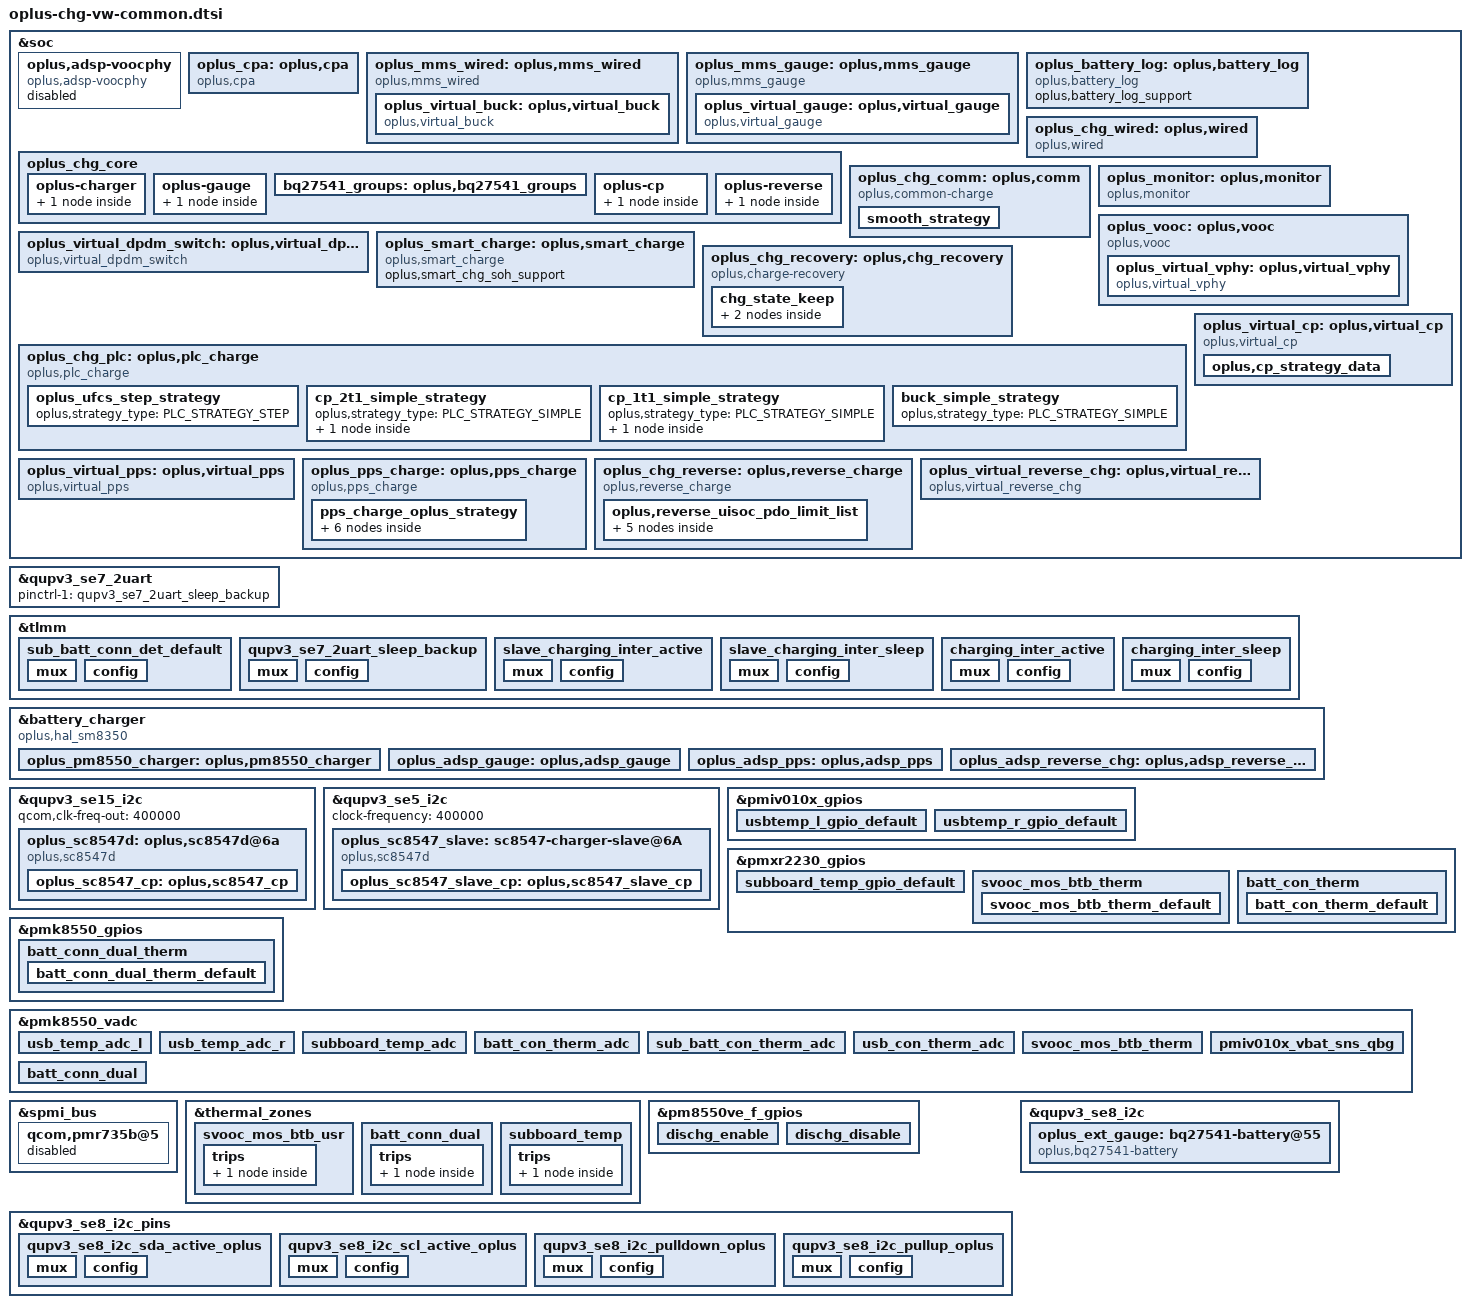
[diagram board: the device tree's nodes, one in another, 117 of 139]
//ifdef OPLUS_FEATURE_CHG_BASIC
#include "../oplus-chg-8750.h.dtsi"
#include <dt-bindings/iio/qcom,spmi-adc5-gen3-pmk8550.h>
#include <dt-bindings/iio/qcom,spmi-adc5-gen3-pm8550.h>
#include <dt-bindings/iio/qcom,spmi-adc5-gen3-pm8550b.h>
#include <dt-bindings/iio/qcom,spmi-adc5-gen3-pm8550vx.h>
#include <dt-bindings/iio/qcom,spmi-adc5-gen3-pmiv0104.h>

&soc {
	oplus,adsp-voocphy {
		status = "disabled";
		compatible = "oplus,adsp-voocphy";
	};
	oplus_cpa: oplus,cpa {
		compatible = "oplus,cpa";
		oplus,protocol_list = <CHG_PROTOCOL_PD   18
					CHG_PROTOCOL_VOOC 80
					CHG_PROTOCOL_QC   18>;
		oplus,default_protocol_list = <CHG_PROTOCOL_PD
						CHG_PROTOCOL_VOOC>;
	};

	oplus_mms_wired: oplus,mms_wired {
		compatible = "oplus,mms_wired";
		oplus,buck_ic = <&oplus_virtual_buck>;
		oplus,voocphy_ic = <&oplus_virtual_vphy>;
		oplus,adc_info_name = "855";
		oplus,topic-update-interval = <5000>;
		high-temp-scheme;
		oplus,support_usbtemp_protect_v2;
		oplus_spec,usbtemp_batt_temp_low = <50>;
		oplus_spec,usbtemp_batt_temp_high = <50>;
		oplus_spec,usbtemp_batt_temp_over_hot = <60>;
		oplus_spec,usbtemp_ntc_temp_low = <57>;
		oplus_spec,usbtemp_ntc_temp_high = <69>;
		oplus_spec,usbtemp_temp_gap_low_with_batt_temp = <7>;
		oplus_spec,usbtemp_temp_gap_with_batt_temp_in_over_hot = <15>;
		oplus_spec,usbtemp_temp_gap_high_with_batt_temp = <12>;
		oplus_spec,usbtemp_temp_gap_low_without_batt_temp = <12>;
		oplus_spec,usbtemp_temp_gap_high_without_batt_temp = <24>;
		oplus_spec,usbtemp_rise_fast_temp_low = <3>;
		oplus_spec,usbtemp_rise_fast_temp_high = <3>;
		oplus_spec,usbtemp_rise_fast_temp_count_low = <30>;
		oplus_spec,usbtemp_rise_fast_temp_count_high = <20>;
		oplus_spec,usbtemp_cool_down_ntc_low = <54>;
		oplus_spec,usbtemp_cool_down_ntc_high = <65>;
		oplus_spec,usbtemp_cool_down_gap_low = <12>;
		oplus_spec,usbtemp_cool_down_gap_high = <20>;
		oplus_spec,usbtemp_cool_down_recover_ntc_low = <48>;
		oplus_spec,usbtemp_cool_down_recover_ntc_high = <60>;
		oplus_spec,usbtemp_cool_down_recover_gap_low = <6>;
		oplus_spec,usbtemp_cool_down_recover_gap_high = <15>;
		oplus_spec,usbtemp_otg_cc_boot_current_limit = <1500>;

		oplus_virtual_buck: oplus,virtual_buck {
			compatible = "oplus,virtual_buck";
			oplus,buck_ic = <&oplus_pm8550_charger>;
			oplus,buck_ic_index = <0>;
			oplus,buck_ic_connect = <OPLUS_CHG_IC_CONNECT_PARALLEL>;
			oplus,main_charger = <1>;
			oplus,buck_ic_current_ratio = <100>;
			oplus,buck_ic_func_group = <&plat_pm8550_groups>;

			oplus,ic_type = <OPLUS_CHG_IC_VIRTUAL_BUCK>;
			oplus,ic_index = <0>;

			oplus,dischg-gpio = <&pm8550ve_f_gpios 7 0x00>;

			pinctrl-names = "usbtemp_l_gpio_default", "usbtemp_r_gpio_default",
					"dischg_enable", "dischg_disable";
			pinctrl-0 = <&usbtemp_l_gpio_default>;
			pinctrl-1 = <&usbtemp_r_gpio_default>;
			pinctrl-2 = <&dischg_enable>;
			pinctrl-3 = <&dischg_disable>;


			io-channels = <&pmk8550_vadc PMIV0104_ADC5_GEN3_AMUX_THM6_GPIO6_100K_PU>,
					      <&pmk8550_vadc PMIV0104_ADC5_GEN3_AMUX3_GPIO7_100K_PU>;
			io-channel-names = "usb_temp_adc_l", "usb_temp_adc_r";

			oplus,uart_tx-gpio = <&tlmm 30 0x00>;
			oplus,uart_rx-gpio = <&tlmm 31 0x00>;
		};
	};

	oplus_mms_gauge: oplus,mms_gauge {
		compatible = "oplus,mms_gauge";
		oplus,gauge_ic = <&oplus_virtual_gauge>;
		oplus,topic-update-interval = <5000>;
		oplus,support_subboard_ntc;
		oplus,sub_btb_curr_limit = <3000>;
		oplus,fcl_support;
		oplus,fcl_index = <0>;
		oplus,vb_offset = <20>;

		oplus_virtual_gauge: oplus,virtual_gauge {
			compatible = "oplus,virtual_gauge";
			oplus,gauge_ic = <&oplus_adsp_gauge &oplus_ext_gauge>;
			oplus,gauge_ic_index = <0 1>;
			oplus,gauge_ic_func_group = <&adsp_gauge_groups &bq27541_groups>;
			oplus,ic_type = <OPLUS_CHG_IC_VIRTUAL_GAUGE>;
			oplus,ic_index = <0>;

			oplus,batt_sub_btb-gpio = <&tlmm 134 0x00>;
			pinctrl-names = "default";
			pinctrl-0 = <&sub_batt_conn_det_default>;
		};
	};

	oplus_chg_core: oplus_chg_core {
		oplus,chg_framework_v2;
		oplus,battery_type_by_smem;
		oplus,smart_charging_screenoff;
		oplus,chg_spec_version = <OPLUS_CHG_SPEC_VER_V3P7>;
		oplus,common-charge-icl-support;

		oplus-charger {
			plat_pm8550_groups: oplus,plat_pm8550-groups {
				functions = <
					OPLUS_IC_FUNC_INIT
					OPLUS_IC_FUNC_EXIT
					OPLUS_IC_FUNC_REG_DUMP
					OPLUS_IC_FUNC_SMT_TEST
					OPLUS_IC_FUNC_BUCK_INPUT_PRESENT
					OPLUS_IC_FUNC_BUCK_INPUT_SUSPEND
					OPLUS_IC_FUNC_BUCK_INPUT_IS_SUSPEND
					OPLUS_IC_FUNC_BUCK_OUTPUT_SUSPEND
					OPLUS_IC_FUNC_BUCK_OUTPUT_IS_SUSPEND
					OPLUS_IC_FUNC_BUCK_GET_CC_ORIENTATION
					OPLUS_IC_FUNC_BUCK_GET_CHARGER_TYPE
					OPLUS_IC_FUNC_BUCK_RERUN_BC12
					OPLUS_IC_FUNC_BUCK_QC_DETECT_ENABLE
					OPLUS_IC_FUNC_BUCK_SHIPMODE_ENABLE
					OPLUS_IC_FUNC_BUCK_SET_QC_CONFIG
					OPLUS_IC_FUNC_BUCK_SET_PD_CONFIG
					OPLUS_IC_FUNC_GET_SHUTDOWN_SOC
					OPLUS_IC_FUNC_BACKUP_SOC
					OPLUS_IC_FUNC_GET_TYPEC_MODE
					OPLUS_IC_FUNC_BUCK_SET_ICL
					OPLUS_IC_FUNC_BUCK_GET_ICL
					OPLUS_IC_FUNC_BUCK_SET_FCC
					OPLUS_IC_FUNC_BUCK_SET_FV
					OPLUS_IC_FUNC_BUCK_SET_ITERM
					OPLUS_IC_FUNC_BUCK_SET_RECHG_VOL
					OPLUS_IC_FUNC_BUCK_GET_INPUT_CURR
					OPLUS_IC_FUNC_BUCK_GET_INPUT_VOL
					OPLUS_IC_FUNC_BUCK_ITEM_CHECK
					OPLUS_IC_FUNC_GET_CHARGER_CYCLE
					OPLUS_IC_FUNC_OTG_BOOST_ENABLE
					OPLUS_IC_FUNC_SET_OTG_BOOST_CURR_LIMIT
					OPLUS_IC_FUNC_BUCK_GET_VBUS_COLLAPSE_STATUS
					OPLUS_IC_FUNC_GET_OTG_ENABLE
					OPLUS_IC_FUNC_SET_OTG_SWITCH_STATUS
					OPLUS_IC_FUNC_GET_OTG_SWITCH_STATUS
					OPLUS_IC_FUNC_GET_OTG_ONLINE_STATUS
					OPLUS_IC_FUNC_BUCK_GET_HW_DETECT
					OPLUS_IC_FUNC_VOOCPHY_SET_MATCH_TEMP
					OPLUS_IC_FUNC_IS_OPLUS_SVID
					OPLUS_IC_FUNC_BUCK_SET_VINDPM
					OPLUS_IC_FUNC_BUCK_DIS_INSERT_DETECT
					OPLUS_IC_FUNC_GET_TYPEC_ROLE
					OPLUS_IC_FUNC_SET_TYPEC_MODE
					OPLUS_IC_FUNC_BUCK_GET_USB_BTB_TEMP
					OPLUS_IC_FUNC_BUCK_GET_BATT_BTB_TEMP
					OPLUS_IC_FUNC_BUCK_GET_TYPEC_STATE
					OPLUS_IC_FUNC_BUCK_GET_USB_AICL_ENHANCE
					OPLUS_IC_FUNC_BUCK_SET_AICL_POINT
					OPLUS_IC_FUNC_BUCK_GET_POWER_ROLE
					OPLUS_IC_FUNC_GET_SOURCE_PDO
					OPLUS_IC_FUNC_BUCK_GET_VDM_INFO
					OPLUS_IC_FUNC_BUCK_SEND_GET_SINK_CAP
				>;
				virqs = <
					OPLUS_IC_VIRQ_ERR
					OPLUS_IC_VIRQ_CC_DETECT
					OPLUS_IC_VIRQ_PLUGIN
					OPLUS_IC_VIRQ_CC_CHANGED
					OPLUS_IC_VIRQ_SUSPEND_CHECK
					OPLUS_IC_VIRQ_CHG_TYPE_CHANGE
					OPLUS_IC_VIRQ_OTG_ENABLE
					OPLUS_IC_VIRQ_SVID
					OPLUS_IC_VIRQ_TYPEC_STATE
					OPLUS_IC_VIRQ_POWER_ROLE_STATUS
					OPLUS_IC_VIRQ_POWER_CHANGED
				>;
			};
		};

		oplus-gauge {
			adsp_gauge_groups: oplus,gauge_groups {
				functions = <
					OPLUS_IC_FUNC_INIT
					OPLUS_IC_FUNC_EXIT
					OPLUS_IC_FUNC_REG_DUMP
					OPLUS_IC_FUNC_SMT_TEST
					OPLUS_IC_FUNC_GAUGE_GET_SUBBOARD_TEMP
				>;
				virqs = <
					OPLUS_IC_VIRQ_ERR
				>;
			};
		};
		bq27541_groups: oplus,bq27541_groups {
			functions = <
				OPLUS_IC_FUNC_INIT
				OPLUS_IC_FUNC_EXIT
				OPLUS_IC_FUNC_REG_DUMP
				OPLUS_IC_FUNC_SMT_TEST
				OPLUS_IC_FUNC_GAUGE_GET_BATT_VOL
				OPLUS_IC_FUNC_GAUGE_GET_BATT_MAX
				OPLUS_IC_FUNC_GAUGE_GET_BATT_MIN
				OPLUS_IC_FUNC_GAUGE_GET_BATT_CURR
				OPLUS_IC_FUNC_GAUGE_GET_BATT_TEMP
				OPLUS_IC_FUNC_GAUGE_GET_BATT_SOC
				OPLUS_IC_FUNC_GAUGE_GET_BATT_FCC
				OPLUS_IC_FUNC_GAUGE_GET_BATT_CC
				OPLUS_IC_FUNC_GAUGE_GET_BATT_RM
				OPLUS_IC_FUNC_GAUGE_GET_BATT_SOH
				OPLUS_IC_FUNC_GAUGE_GET_BATT_AUTH
				OPLUS_IC_FUNC_GAUGE_GET_BATT_HMAC
				/* TODO: remove the battery full to fix the issue of force report full*/
				/* OPLUS_IC_FUNC_GAUGE_SET_BATT_FULL */
				OPLUS_IC_FUNC_GAUGE_UPDATE_DOD0
				OPLUS_IC_FUNC_GAUGE_UPDATE_SOC_SMOOTH
				OPLUS_IC_FUNC_GAUGE_GET_CB_STATUS
				OPLUS_IC_FUNC_GAUGE_GET_BATT_NUM
				OPLUS_IC_FUNC_GAUGE_GET_DEVICE_TYPE
				OPLUS_IC_FUNC_GAUGE_GET_DEVICE_TYPE_FOR_VOOC
				OPLUS_IC_FUNC_GAUGE_GET_BATT_FCC
				OPLUS_IC_FUNC_GAUGE_GET_BATT_FC
				OPLUS_IC_FUNC_GAUGE_GET_BATT_QM
				OPLUS_IC_FUNC_GAUGE_GET_BATT_PD
				OPLUS_IC_FUNC_GAUGE_GET_BATT_RCU
				OPLUS_IC_FUNC_GAUGE_GET_BATT_RCF
				OPLUS_IC_FUNC_GAUGE_GET_BATT_FCU
				OPLUS_IC_FUNC_GAUGE_GET_BATT_FCF
				OPLUS_IC_FUNC_GAUGE_GET_BATT_SOU
				OPLUS_IC_FUNC_GAUGE_GET_BATT_DO0
				OPLUS_IC_FUNC_GAUGE_GET_BATT_DOE
				OPLUS_IC_FUNC_GAUGE_GET_BATT_TRM
				OPLUS_IC_FUNC_GAUGE_GET_BATT_PC
				OPLUS_IC_FUNC_GAUGE_GET_BATT_QS
				OPLUS_IC_FUNC_GAUGE_IS_SUSPEND
				OPLUS_IC_FUNC_GAUGE_GET_BCC_PARMS
				OPLUS_IC_FUNC_GAUGE_FASTCHG_UPDATE_BCC_PARMS
				OPLUS_IC_FUNC_GAUGE_GET_PREV_BCC_PARMS
				OPLUS_IC_FUNC_GAUGE_SET_BCC_PARMS
				OPLUS_IC_FUNC_GAUGE_GET_DEVICE_TYPE_FOR_BCC
				OPLUS_IC_FUNC_GAUGE_GET_DOD0
				OPLUS_IC_FUNC_GAUGE_GET_DOD0_PASSED_Q
				OPLUS_IC_FUNC_GAUGE_GET_QMAX
				OPLUS_IC_FUNC_GAUGE_GET_QMAX_PASSED_Q
				OPLUS_IC_FUNC_GAUGE_GET_DEEP_DISCHG_COUNT
				OPLUS_IC_FUNC_GAUGE_SET_DEEP_DISCHG_COUNT
				OPLUS_IC_FUNC_GAUGE_SET_DEEP_TERM_VOLT
				OPLUS_IC_FUNC_GAUGE_GET_REG_INFO
				OPLUS_IC_FUNC_GAUGE_GET_CALIB_TIME
				OPLUS_IC_FUNC_GAUGE_GET_BATT_SN
				OPLUS_IC_FUNC_GAUGE_GET_DEEP_TERM_VOLT
				OPLUS_IC_FUNC_GAUGE_SET_SILI_SPARE_POWER
				OPLUS_IC_FUNC_GAUGE_GET_SILI_SIMULATE_TERM_VOLT
				OPLUS_IC_FUNC_GAUGE_GET_SILI_IC_ALG_TERM_VOLT
				OPLUS_IC_FUNC_GAUGE_SET_SILI_IC_ALG_CFG
				OPLUS_IC_FUNC_GAUGE_GET_SILI_IC_ALG_DSG_ENABLE
				OPLUS_IC_FUNC_GAUGE_SET_SILI_IC_ALG_TERM_VOLT
				OPLUS_IC_FUNC_GAUGE_GET_SILI_ALG_APPLICATION_INFO
				OPLUS_IC_FUNC_GAUGE_GET_SILI_LIFETIME_STATUS
				OPLUS_IC_FUNC_GAUGE_GET_SILI_LIFETIME_INFO
				OPLUS_IC_FUNC_GAUGE_GET_MANU_DATE
				OPLUS_IC_FUNC_GAUGE_GET_FIRST_USAGE_DATE
				OPLUS_IC_FUNC_GAUGE_SET_FIRST_USAGE_DATE
				OPLUS_IC_FUNC_GAUGE_GET_UI_CC
				OPLUS_IC_FUNC_GAUGE_SET_UI_CC
				OPLUS_IC_FUNC_GAUGE_GET_UI_SOH
				OPLUS_IC_FUNC_GAUGE_SET_UI_SOH
				OPLUS_IC_FUNC_GAUGE_GET_USED_FLAG
				OPLUS_IC_FUNC_GAUGE_SET_USED_FLAG
				OPLUS_IC_FUNC_GAUGE_SET_CALIB_TIME
				OPLUS_IC_FUNC_GAUGE_SET_LAST_CC
				OPLUS_IC_FUNC_GAUGE_GET_LAST_CC
				OPLUS_IC_FUNC_GAUGE_GET_CHEM_ID
				OPLUS_IC_FUNC_GAUGE_GET_DEC_FG_TYPE
				OPLUS_IC_FUNC_GAUGE_GET_DEC_CV_SOH
				OPLUS_IC_FUNC_GAUGE_SET_VCT
				OPLUS_IC_FUNC_GAUGE_GET_VCT
				OPLUS_IC_FUNC_GAUGE_GET_BATT_SOC_CENTI
				OPLUS_IC_FUNC_GAUGE_GET_SUB_BTB_CONNECT_STATE
				OPLUS_IC_FUNC_GAUGE_GET_GAUGE_CAR_C
			>;
			virqs = <
				OPLUS_IC_VIRQ_ERR
				OPLUS_IC_VIRQ_OFFLINE
				OPLUS_IC_VIRQ_RESUME
			>;
		};

		oplus-cp {
			sc8547_cp_groups: oplus,cp_groups {
			functions = <
					OPLUS_IC_FUNC_INIT
					OPLUS_IC_FUNC_EXIT
					OPLUS_IC_FUNC_REG_DUMP
					OPLUS_IC_FUNC_SMT_TEST
					OPLUS_IC_FUNC_CP_ENABLE
					OPLUS_IC_FUNC_CP_HW_INTI
					OPLUS_IC_FUNC_CP_SET_WORK_START
					OPLUS_IC_FUNC_CP_CHECK_WORK_MODE_SUPPORT
					OPLUS_IC_FUNC_CP_SET_WORK_MODE
					OPLUS_IC_FUNC_CP_GET_WORK_MODE
					OPLUS_IC_FUNC_CP_GET_VIN
					OPLUS_IC_FUNC_CP_GET_IIN
					OPLUS_IC_FUNC_CP_SET_IIN
					OPLUS_IC_FUNC_CP_GET_VOUT
					OPLUS_IC_FUNC_CP_GET_IOUT
					OPLUS_IC_FUNC_CP_GET_VAC
					OPLUS_IC_FUNC_CP_GET_WORK_STATUS
					OPLUS_IC_FUNC_CP_SET_ADC_ENABLE
					OPLUS_IC_FUNC_CP_WATCHDOG_ENABLE
					OPLUS_IC_FUNC_CP_SET_UCP_DISABLE
					OPLUS_IC_FUNC_CP_GET_IIN_MAX
					OPLUS_IC_FUNC_CP_WATCHDOG_RESET
					OPLUS_IC_FUNC_CP_SET_SSTIMEOUT_UCP_ENABLE
				>;
				virqs = <
					OPLUS_IC_VIRQ_ERR
					OPLUS_IC_VIRQ_ONLINE
					OPLUS_IC_VIRQ_OFFLINE
				>;
			};
		};

		oplus-reverse {
			pmk8550_reverse_chg: oplus,pmk8550_reverse_chg {
				functions = <
					OPLUS_IC_FUNC_INIT
					OPLUS_IC_FUNC_EXIT
					OPLUS_IC_FUNC_REG_DUMP
					OPLUS_IC_FUNC_SMT_TEST
					OPLUS_IC_FUNC_GET_REVERSE_ENABLE
					OPLUS_IC_FUNC_SET_REVERSE_SRC_PDO
					OPLUS_IC_FUNC_GET_REVERSE_CHG_SVID
					OPLUS_IC_FUNC_GET_HIGH_REVERSE_ENABLE
					OPLUS_IC_FUNC_GET_RVS_CHG_MSG
					OPLUS_IC_FUNC_GET_SINK_REQ_PDO
					OPLUS_IC_FUNC_RVS_SET_HIGH_PWR_MODE_EN
				>;
				virqs = <
					OPLUS_IC_VIRQ_ERR
					OPLUS_IC_VIRQ_ONLINE
					OPLUS_IC_VIRQ_OFFLINE
					OPLUS_IC_VIRQ_REVERSE_ENABLE
					OPLUS_IC_VIRQ_HIGH_REVERSE_ENABLE
					OPLUS_IC_VIRQ_HARD_RESET
					OPLUS_IC_VIRQ_SINK_REQ_MSG
				>;
			};
		};
	};

	oplus_battery_log: oplus,battery_log {
		compatible = "oplus,battery_log";

		oplus,battery_log_support;
	};

	oplus_chg_wired: oplus,wired {
		compatible = "oplus,wired";

		oplus,vooc-support;

		oplus_spec,vbatt_pdqc_to_5v_thr = <5100>;
		oplus_spec,vbatt_pdqc_to_9v_thr = <5000>;
		oplus_spec,pd-iclmax-ma = <2000>;
		oplus_spec,qc-iclmax-ma = <2000>;
		oplus_spec,non-standard-ibatmax-ma = <500>;
		oplus_spec,input-power-mw = <
			2500		/* OPLUS_WIRED_CHG_MODE_UNKNOWN */
			2500		/* OPLUS_WIRED_CHG_MODE_SDP */
			7500		/* OPLUS_WIRED_CHG_MODE_CDP */
			10000		/* OPLUS_WIRED_CHG_MODE_DCP */
			30000		/* OPLUS_WIRED_CHG_MODE_VOOC */
			13500		/* OPLUS_WIRED_CHG_MODE_QC */
			13500		/* OPLUS_WIRED_CHG_MODE_PD */
		>;

		oplus_spec,cool_down_sale_pdqc_vol_mv = <5000>;
		oplus_spec,cool_down_sale_pdqc_curr_ma = <1200>;
		oplus_spec,cool_down_pdqc_vol_mv = <5000 5000 5000 9000>;
		oplus_spec,cool_down_pdqc_curr_ma = <1200 1500 2000 1500>;
		oplus_spec,cool_down_vooc_curr_ma = <1200 1500 2000 2500 3000 3000>;
		oplus_spec,cool_down_normal_curr_ma = <1200 1500 2000>;

		oplus_spec,vbus_ov_thr_mv = <11000 11000>;
		oplus_spec,vbus_uv_thr_mv = <4300 4300>;

		/* first data is strategy used temp type */
		oplus,pd_strategy_name = "cgcl";
		oplus,pd_strategy_data = <OPLUS_STRATEGY_USE_SHELL_TEMP
					    0   420 2000 1 0
					    410 430 1500 2 0
					    420 440 1200 2 1>;
		oplus,qc_strategy_name = "cgcl";
		oplus,qc_strategy_data = <OPLUS_STRATEGY_USE_SHELL_TEMP
					    0   420 2000 1 0
					    410 430 1500 2 0
					    420 440 1200 2 1>;
	};

	oplus_chg_comm: oplus,comm {
		compatible = "oplus,common-charge";
		oplus_spec,batt-them-thr = <(-100) 0 50 120 160 350 450 530>;
		oplus_spec,removed_bat_decidegc = <390>; /*-39 degree*/

		oplus_spec,hw-fv-inc-mv = <0 18 18 18 18 18 18 18 0>;

		oplus_spec,sw-over-fv-dec-mv = <10>;
		oplus_spec,non-standard-sw-fv-mv = <3930>;
		oplus_spec,non-standard-fv-mv = <3980>;
		oplus_spec,non-standard-hw-fv-inc-mv = <18>;
		oplus_spec,non-standard-sw-over-fv-mv = <3988>;
		oplus_spec,non-standard-vbatdet-mv = <3680>;
		oplus_spec,fcc-gear-shake-mv = <400 400 400 300 300 180 180 180 180>;
		oplus_spec,vbatt-ov-thr-mv = <4600>;
		oplus_spec,sw_check_full_cnt = <12>;


		/*If use subboard NTC as battery temp, config it as 20, otherwise 0 */
		oplus_spec,tbatt_power_off_cali_temp = <0>;
		oplus,vooc_show_ui_soc_decimal;
		oplus,ui_soc_decimal_speedmin = <20>;
		oplus_spec,poweroff_high_batt_temp = <720>;
		oplus_spec,poweroff_emergency_batt_temp = <770>;
		oplus,gauge_stuck_jump_support;
		oplus,gauge_stuck_threshold = <15>;
		oplus,gauge_stuck_time = <50>;
		oplus_spec,batt_full_time = <60>;
		oplus_spec,batt_full_low_soc = <99>;
		oplus_spec,batt_full_low_soc_time = <600>;
		oplus_spec,smooth_strategy_name = "bs";
		oplus_spec,hw_iterm_support;
		smooth_strategy {
			oplus_spec,reserve_table_centipercent =
				/* start(%) end(%) dischg_reserve(0.01%) full_reserve(0.01%) chg_reserve(0.01%) chg_split(%) */
				<0   20  0   0   200 100>,
				<21  99  200 0   200 100>,
				<100 100 200 0   200 100>;
		};
	};

	oplus_monitor: oplus,monitor {
		compatible = "oplus,monitor";
		oplus,topic-update-interval = <60000>;

		track,fast_chg_break_t_thd = <2500>;
		track,general_chg_break_t_thd = <300>;
		track,voocphy_type = <3>;
		track,wired_max_power = <80000>;
		track,wired_fast_chg_scheme = <2>;

		track,gauge_status_ctrl;
		track,external_gauge_num = <1>;
		track,low_soc_monitor_ctrl;

		track,gauge_max_cell_vol = <4600>;
		track,gauge_max_charge_curr = <13000>;
		track,gauge_max_dischg_curr = <6000>;
		track,gauge_min_cell_temp = <30>;
		track,gauge_max_cell_temp = <70>;
		track,gauge_lifetime_support;
		track,track_ver = <TRACK_VER_4_0>;
	};

	oplus_vooc: oplus,vooc {
		compatible = "oplus,vooc";
		oplus,vooc_ic = <&oplus_virtual_vphy>;

		oplus_spec,vooc_soc_range = <55 75 85>;

		oplus,vooc_data_width = <7>;
		oplus,vooc_curr_max = <CP_CURR_LIMIT_7BIT_15_0A>; /* 80W: 11V 7.3A(IBUS *2) */
		oplus,vooc_power_max_w = <80>;
		oplus,vooc_project = <VOOC_PROJECT_10V8A_TWO_BAT_SVOOC>;
		oplus,vooc_curr_table_type = <VOOC_CP_CURR_TABLE>;
		oplus,voocphy_support = <3>; /* AP_DUAL_CP_VOOCPHY */
		oplus,support_fake_vooc_check;
		oplus,subboard_ntc_abnormal_current = <4000>;

		/* first data is strategy used temp type */
		oplus,general_strategy_name = "cgcl";
		oplus,general_strategy_data = <OPLUS_STRATEGY_USE_SHELL_TEMP
						0   385 CP_CURR_LIMIT_7BIT_15_0A 1 0
						375 405 CP_CURR_LIMIT_7BIT_10_0A 2 0
						395 420 CP_CURR_LIMIT_7BIT_8_0A  3 1
						410 430 CP_CURR_LIMIT_7BIT_7_0A  4 2
						420 440 CP_CURR_LIMIT_7BIT_6_0A  4 3>;

		oplus,bypass_strategy_name = "cgcl";
		oplus,bypass_strategy_data = <OPLUS_STRATEGY_USE_SHELL_TEMP
						0   395 CP_CURR_LIMIT_7BIT_6_0A  1 0
						385 405 CP_CURR_LIMIT_7BIT_4_0A  2 0
						395 415 CP_CURR_LIMIT_7BIT_3_0A  3 1
						405 440 CP_CURR_LIMIT_7BIT_2_0A  3 2>;
		oplus,plc_strategy-data = <&buck_simple_strategy &cp_2t1_simple_strategy &cp_1t1_simple_strategy>;
		oplus,plc_strategy-names = "default", "svooc", "vooc";
		oplus,cp_cooldown_limit_percent_75 = <CP_CURR_LIMIT_7BIT_4_0A>;
 		oplus,cp_cooldown_limit_percent_85 = <CP_CURR_LIMIT_7BIT_2_0A>;

		oplus_virtual_vphy: oplus,virtual_vphy {
			compatible = "oplus,virtual_vphy";
			oplus,vphy_ic = <&oplus_sc8547d>;
			oplus,dpdm_switch_ic = <&oplus_virtual_dpdm_switch>;

			oplus,ic_type = <OPLUS_CHG_IC_VIRTUAL_VPHY>;
			oplus,ic_index = <0>;
		};
	};

	oplus_virtual_dpdm_switch: oplus,virtual_dpdm_switch {
		compatible = "oplus,virtual_dpdm_switch";

		oplus,ic_type = <OPLUS_CHG_IC_MISC>;
		oplus,ic_index = <0>;
	};

	oplus_smart_charge: oplus,smart_charge {
		compatible = "oplus,smart_charge";
		oplus,smart_chg_soh_support;
	};


	oplus_chg_recovery: oplus,chg_recovery {
		compatible = "oplus,charge-recovery";

		chg_state_keep {
			wired_disconnect_detection {
				protocol_switch_table = <
					CHG_PROTOCOL_UFCS  44  3  3
					CHG_PROTOCOL_PPS    0  3  3
					CHG_PROTOCOL_VOOC   0  0  0
					CHG_PROTOCOL_PD     0  3  3
					CHG_PROTOCOL_QC     0  3  3
					CHG_PROTOCOL_BC12   0  3  3
				>;
			};
			vooc_disconnect_detection {};
		};
	};

	oplus_chg_plc: oplus,plc_charge {
		compatible = "oplus,plc_charge";
		oplus,plc_soc = <90>;
		oplus,plc_support_timeout;
		oplus,plc_strategy-data = <&buck_simple_strategy>;
		oplus,plc_strategy-names = "default";
		status = "okay";

		oplus_ufcs_step_strategy: oplus_ufcs_step_strategy {
			oplus,strategy_type = <PLC_STRATEGY_STEP>;
		};

		cp_2t1_simple_strategy: cp_2t1_simple_strategy {
			oplus,strategy_type = <PLC_STRATEGY_SIMPLE>;
			oplus,strategy_data {
				strategy_curr_ma = <1000 1500>;
			};
		};

		cp_1t1_simple_strategy: cp_1t1_simple_strategy {
			oplus,strategy_type = <PLC_STRATEGY_SIMPLE>;
			oplus,strategy_data {
				strategy_curr_ma = <2000 3000>;
			};
		};

		buck_simple_strategy: buck_simple_strategy {
			oplus,strategy_type = <PLC_STRATEGY_SIMPLE>;
		};
	};

	oplus_virtual_cp: oplus,virtual_cp {
		compatible = "oplus,virtual_cp";

		oplus,ic_type = <OPLUS_CHG_IC_VIRTUAL_CP>;
		oplus,ic_index = <0>;

		oplus,cp_ic = <&oplus_sc8547_cp &oplus_sc8547_slave_cp>;
		oplus,input_curr_max_ma = <4000 4000>;

		oplus,cp_ic_connect = <OPLUS_CHG_IC_CONNECT_PARALLEL>;
		oplus,main_cp = <0>;

		oplus,reg_proc_node;

		oplus,cp_strategy = <CP_STRAT_OPEN_BY_CURR>;
		oplus,cp_strategy_data {
			oplus,cp_open_curr_thr_ma = <0 1900>;
			oplus,cp_close_curr_thr_ma = <0 1600>;
		};
	};

	oplus_virtual_pps: oplus,virtual_pps {
		compatible = "oplus,virtual_pps";

		oplus,ic_type = <OPLUS_CHG_IC_VIRTUAL_PPS>;
		oplus,ic_index = <0>;
		oplus,pps_ic = <&oplus_adsp_pps>;
	};

	oplus_pps_charge: oplus,pps_charge {
		compatible = "oplus,pps_charge";
		oplus,pps_ic = <&oplus_virtual_pps>;
		oplus,cp_ic = <&oplus_virtual_cp>;
		oplus,dpdm_switch_ic = <&oplus_virtual_dpdm_switch>;


		oplus,plc_strategy-data = <&cp_2t1_simple_strategy>;
		oplus,plc_strategy-names = "default";

		pps_charge_oplus_strategy {
			oplus,temp_type = <OPLUS_STRATEGY_USE_SHELL_TEMP>;
			oplus,soc_range = <0 20 35 55 75 85 90>;
			oplus,temp_range = <0 50 120 160 210 350 440 510>;

			strategy_soc_range_min { /* 0 ~ 20 */
				strategy_temp_little_cold =	<11000 4150 2200 0 0
								 11000 4150 2000 0 0
								 11000 4480 1550 0 0
								 11000 4480 1500 0 0
								 11000 4490 1000 1 0>;
				strategy_temp_cool =		<11000 4280 5000 0 0
								 11000 4480 2600 0 0
								 11000 4480 2500 0 0
								 11000 4480 2000 0 0
								 11000 4480 1500 0 0
								 11000 4490 1000 1 0>;
				strategy_temp_little_cool =	<11000 4480 5000 0 0
								 11000 4480 2500 0 0
								 11000 4480 2000 0 0
								 11000 4480 1500 0 0
								 11000 4490 1000 1 0>;
				strategy_temp_little_cool_high =<11000 4480 5000 0 0
								 11000 4480 2500 0 0
								 11000 4480 2000 0 0
								 11000 4480 1500 0 0
								 11000 4490 1000 1 0>;
				strategy_temp_normal_low =	<11000 4480 5000 0 0
								 11000 4480 2500 0 0
								 11000 4480 2000 0 0
								 11000 4480 1800 0 0
								 11000 4480 1500 0 0
								 11000 4490 1000 1 0>;
				strategy_temp_normal_high =	<11000 4460 5000 0 0
								 11000 4460 2500 0 0
								 11000 4460 2450 0 0
								 11000 4460 2000 0 0
								 11000 4460 1500 0 0
								 11000 4470 1000 1 0>;
				strategy_temp_warm =		<11000 4120 1850 0 0
								 11000 4120 1500 0 0
								 11000 4130 1000 1 0>;
			};
			strategy_soc_range_low { /* 21 ~ 35 */
				strategy_temp_little_cold =	<11000 4150 2200 0 0
								 11000 4150 2000 0 0
								 11000 4480 1550 0 0
								 11000 4480 1500 0 0
								 11000 4490 1000 1 0>;
				strategy_temp_cool =		<11000 4280 5000 0 0
								 11000 4480 2600 0 0
								 11000 4480 2500 0 0
								 11000 4480 2000 0 0
								 11000 4480 1500 0 0
								 11000 4490 1000 1 0>;
				strategy_temp_little_cool =	<11000 4480 5000 0 0
								 11000 4480 2500 0 0
								 11000 4480 2000 0 0
								 11000 4480 1500 0 0
								 11000 4490 1000 1 0>;
				strategy_temp_little_cool_high =<11000 4480 5000 0 0
								 11000 4480 2500 0 0
								 11000 4480 2000 0 0
								 11000 4480 1500 0 0
								 11000 4490 1000 1 0>;
				strategy_temp_normal_low =	<11000 4480 5000 0 0
								 11000 4480 2500 0 0
								 11000 4480 2000 0 0
								 11000 4480 1800 0 0
								 11000 4480 1500 0 0
								 11000 4490 1000 1 0>;
				strategy_temp_normal_high =	<11000 4460 5000 0 0
								 11000 4460 2500 0 0
								 11000 4460 2450 0 0
								 11000 4460 2000 0 0
								 11000 4460 1500 0 0
								 11000 4470 1000 1 0>;
				strategy_temp_warm =		<11000 4120 1850 0 0
								 11000 4120 1500 0 0
								 11000 4130 1000 1 0>;
			};
			strategy_soc_range_mid_low { /* 36 ~ 55 */
				strategy_temp_little_cold =	<11000 4150 2200 0 0
								 11000 4150 2000 0 0
								 11000 4480 1550 0 0
								 11000 4480 1500 0 0
								 11000 4490 1000 1 0>;
				strategy_temp_cool =		<11000 4280 5000 0 0
								 11000 4480 2600 0 0
								 11000 4480 2500 0 0
								 11000 4480 2000 0 0
								 11000 4480 1500 0 0
								 11000 4490 1000 1 0>;
				strategy_temp_little_cool =	<11000 4480 5000 0 0
								 11000 4480 2500 0 0
								 11000 4480 2000 0 0
								 11000 4480 1500 0 0
								 11000 4490 1000 1 0>;
				strategy_temp_little_cool_high =<11000 4480 5000 0 0
								 11000 4480 2500 0 0
								 11000 4480 2000 0 0
								 11000 4480 1500 0 0
								 11000 4490 1000 1 0>;
				strategy_temp_normal_low =	<11000 4480 5000 0 0
								 11000 4480 2500 0 0
								 11000 4480 2000 0 0
								 11000 4480 1800 0 0
								 11000 4480 1500 0 0
								 11000 4490 1000 1 0>;
				strategy_temp_normal_high =	<11000 4460 5000 0 0
								 11000 4460 2500 0 0
								 11000 4460 2450 0 0
								 11000 4460 2000 0 0
								 11000 4460 1500 0 0
								 11000 4470 1000 1 0>;
				strategy_temp_warm =		<11000 4120 1850 0 0
								 11000 4120 1500 0 0
								 11000 4130 1000 1 0>;
			};
			strategy_soc_range_mid { /* 56 ~ 75*/
				strategy_temp_little_cold =	<11000 4480 1500 0 0
								 11000 4490 1000 1 0>;
				strategy_temp_cool =		<11000 4480 1500 0 0
								 11000 4490 1000 1 0>;
				strategy_temp_little_cool =	<11000 4480 2000 0 0
								 11000 4480 1500 0 0
								 11000 4490 1000 1 0>;
				strategy_temp_little_cool_high =<11000 4480 2000 0 0
								 11000 4480 1500 0 0
								 11000 4490 1000 1 0>;
				strategy_temp_normal_low =	<11000 4480 2500 0 0
								 11000 4480 2000 0 0
								 11000 4480 1800 0 0
								 11000 4480 1500 0 0
								 11000 4490 1000 1 0>;
				strategy_temp_normal_high =	<11000 4460 5000 0 0
								 11000 4460 2500 0 0
								 11000 4460 2450 0 0
								 11000 4460 2000 0 0
								 11000 4460 1500 0 0
								 11000 4470 1000 1 0>;
				strategy_temp_warm =		<11000 4130 1000 1 0>;
			};
			strategy_soc_range_mid_high { /* 76 ~ 85 */
				strategy_temp_little_cold =	<11000 4490 1000 1 0>;
				strategy_temp_cool =		<11000 4490 1000 1 0>;
				strategy_temp_little_cool =	<11000 4480 1500 0 0
								 11000 4490 1000 1 0>;
				strategy_temp_little_cool_high =<11000 4480 1500 0 0
								 11000 4490 1000 1 0>;
				strategy_temp_normal_low =	<11000 4480 2000 0 0
								 11000 4480 1800 0 0
								 11000 4480 1500 0 0
								 11000 4490 1000 1 0>;
				strategy_temp_normal_high =	<11000 4460 2500 0 0
								 11000 4460 2450 0 0
								 11000 4460 2000 0 0
								 11000 4460 1500 0 0
								 11000 4470 1000 1 0>;
				strategy_temp_warm =		<11000 4130 1000 1 0>;
			};
			strategy_soc_range_high { /* 86 ~ 90 */
				strategy_temp_little_cold =	<11000 4490 1000 1 0>;
				strategy_temp_cool =		<11000 4490 1000 1 0>;
				strategy_temp_little_cool =	<11000 4490 1000 1 0>;
				strategy_temp_little_cool_high =<11000 4490 1000 1 0>;
				strategy_temp_normal_low =	<11000 4480 1800 0 0
								 11000 4480 1500 0 0
								 11000 4490 1000 1 0>;
				strategy_temp_normal_high =	<11000 4460 2450 0 0
								 11000 4460 2000 0 0
								 11000 4460 1500 0 0
								 11000 4470 1000 1 0>;
				strategy_temp_warm =		<11000 4130 1000 1 0>;
			};
		};
	};

	oplus_chg_reverse: oplus,reverse_charge {
		compatible = "oplus,reverse_charge";
		oplus,reverse_ic = <&oplus_virtual_reverse_chg>;
		oplus,buck_ic = <&oplus_virtual_buck>;
		oplus,use_high_reverse_awake;
		oplus_spec,reverse-uisoc-limit = <66 76 81 91>;
		oplus_spec,reverse-temp-limit = <0 100 400 470>;
		oplus_spec,reverse-vbus-limit = <7300 7400 7500 7500 7700>;
		oplus,reverse_ibus_lower_oplus = <1000>;
		oplus,reset_watchdog_time = <5000>;

		oplus_spec,last-uisoc-limit = <1 20>;
		oplus_spec,last-current = <500 1000>;

		oplus,reverse_vbus_pdo_limit_list = <
					5000 1300 /* 5v1.3a */
					9000 1000
					9000 1500
					9000 2000
					9000 2000
					9000 3000>;

		oplus_spec,reverse-led-on-limit = <9000 1000>;
		oplus_spec,reverse-authenticate-limit = <5000 1300>;
		oplus_spec,reverse-over-ibus-limit = <5000 1300>;

		oplus,reverse_uisoc_pdo_limit_list {
			reverse_uisoc_range_min_pdo_limit_list {
				temp_level_range_cold = <5000 1300>;
				temp_level_range_cool = <5000 1300>;
				temp_level_range_normal = <5000 1300>;
				temp_level_range_warm = <5000 1000>;
				temp_level_range_high = <5000 1000>;
			};

			reverse_uisoc_range_mid_pdo_limit_list {
				temp_level_range_cold = <5000 1300>;
				temp_level_range_cool = <9000 1000>;
				temp_level_range_normal = <9000 1500>;
				temp_level_range_warm = <9000 1000>;
				temp_level_range_high = <5000 1000>;
			};

			reverse_uisoc_range_normal_pdo_limit_list {
				temp_level_range_cold = <5000 1300>;
				temp_level_range_cool = <9000 1000>;
				temp_level_range_normal = <9000 2000>;
				temp_level_range_warm = <9000 1000>;
				temp_level_range_high = <5000 1000>;
			};

			reverse_uisoc_range_mid_high_pdo_limit_list {
				temp_level_range_cold = <5000 1300>;
				temp_level_range_cool = <9000 1000>;
				temp_level_range_normal = <9000 2000>;
				temp_level_range_warm = <9000 1000>;
				temp_level_range_high = <5000 1000>;
			};

			reverse_uisoc_range_high_pdo_limit_list {
				temp_level_range_cold = <5000 1300>;
				temp_level_range_cool = <9000 1000>;
				temp_level_range_normal = <9000 3000>;
				temp_level_range_warm = <9000 1000>;
				temp_level_range_high = <5000 1000>;
			};
		};
	};

	oplus_virtual_reverse_chg: oplus,virtual_reverse_chg {
			compatible = "oplus,virtual_reverse_chg";
			oplus,reverse_chg_ic = <&oplus_adsp_reverse_chg>;
			oplus,reverse_chg_ic_index = <0 1 2>;
			oplus,reverse_chg_ic_func_group = <&pmk8550_reverse_chg>;

			oplus,ic_type = <OPLUS_CHG_IC_VIRTUAL_REVERSE>;
			oplus,ic_index = <0>;
	};
};

&qupv3_se7_2uart {
	pinctrl-1 = <&qupv3_se7_2uart_sleep_backup>;
	status = "okay";
};

&tlmm {
	sub_batt_conn_det_default: sub_batt_conn_det_default{
		mux {
			pins = "gpio134";
			function = "gpio";
		};

		config {
			pins = "gpio134";
			drive-strength = <2>;
			bias-pull-up;
			input-enable;
		};
	};
	qupv3_se7_2uart_sleep_backup:qupv3_se7_2uart_sleep_backup {
		mux {
			pins = "gpio30", "gpio31";
			function = "gpio";
		};

		config {
			pins = "gpio30", "gpio31";
			drive-strength = <2>;
			bias-disable;
			input-enable;
		};
	};
	slave_charging_inter_active: slave_charging_inter_active {
		mux {
			pins = "gpio47";
			function = "gpio";
		};
		config {
			pins = "gpio47";
			bias-pull-up;
			drive-strength = <2>;
			input-enable;
		};
	};

	slave_charging_inter_sleep: slave_charging_inter_sleep {
		mux {
			pins = "gpio47";
			function = "gpio";
		};
		config {
			pins = "gpio47";
			bias-pull-up;
			drive-strength = <2>;
			input-enable;
		};
	};
};

&battery_charger {
	//for oplus chg framework:
	compatible = "oplus,hal_sm8350";

	oplus,chg_ops = "plat-pmic";
	qcom,pmic_ftm_vph = "/sys/bus/spmi/drivers/pmic-spmi/0-00/c42d000.qcom,spmi:qcom,pmk8550@0:vadc@9000/iio:device0/in_voltage_pmiv010x_vph_pwr_input";
	qcom,pmic_ftm_vbat = "/sys/bus/spmi/drivers/pmic-spmi/0-00/c42d000.qcom,spmi:qcom,pmk8550@0:vadc@9000/iio:device0/in_voltage_pmiv010x_vbat_sns_qbg_input";

	pinctrl-names = "subboard_temp_gpio_default";
	pinctrl-0 = <&subboard_temp_gpio_default>;


/* QCOM QBG full param, depend on adapter type and temp_region */
	oplus,batt_full_method_new;
	oplus,batt_full_temp = <(-100) 120 210 440>;
	oplus,batt_full_para = <1351 1351 1351 1351      /* normal pd qc */
				1551 1951 3551 1351      /* svooc */
				1551 1951 3551 1351      /* oplus ufcs */
				1551 1951 3551 1351      /* oplus pps */
				1351 1351 1351 1351      /* third ufcs */
				1351 1351 1351 1351      /* third pps */
				1351 1351 1351 1351>;    /* ffc */
	oplus,voocphy_support;
	qcom,otg_boost_src = <0>;//0:plat_pmic 1:external
	oplus,batt_num = <1>;
	oplus,otg_scheme = <0>;//0:cid 1:ccdetect_gpio 2:switch
	oplus,bypass_vooc_support;
	oplus,usb_aicl_enhance;
	oplus,ufcs_run_check_support;
	oplus,adsp_reboot_discnt_chg_support;

	oplus_pm8550_charger: oplus,pm8550_charger {
		oplus,ic_type = <OPLUS_CHG_IC_BUCK>;
		oplus,ic_index = <0>;
	};

	oplus_adsp_gauge: oplus,adsp_gauge {
		oplus,ic_type = <OPLUS_CHG_IC_GAUGE>;
		oplus,ic_index = <0>;
	};

	oplus_adsp_pps: oplus,adsp_pps {
		oplus,ic_type = <OPLUS_CHG_IC_PPS>;
		oplus,ic_index = <0>;
	};

	oplus_adsp_reverse_chg: oplus,adsp_reverse_chg {
		oplus,ic_type = <OPLUS_CHG_IC_REVERSE>;
		oplus,ic_index = <0>;
	};
};

&battery_charger {
	io-channels = <&pmk8550_vadc PMIV0104_ADC5_GEN3_AMUX_THM6_GPIO6_100K_PU>,
			<&pmk8550_vadc PMIV0104_ADC5_GEN3_AMUX3_GPIO7_100K_PU>,
			<&pmk8550_vadc PM8550_ADC5_GEN3_AMUX2_GPIO4_100K_PU>,
			<&pmk8550_vadc PM8550_ADC5_GEN3_AMUX3_GPIO7_100K_PU>,
			<&pmk8550_vadc PMIV0104_ADC5_GEN3_AMUX_THM4_USB_THERM_100K_PU>,
			<&pmk8550_vadc PM8550_ADC5_GEN3_AMUX1_GPIO3_100K_PU>,
			<&pmk8550_vadc PMK8550_ADC5_GEN3_AMUX_THM2_GPIO1_100K_PU>;
	io-channel-names = "usb_temp_adc_l", "usb_temp_adc_r", "subboard_temp_adc",
				"batt_con_therm_adc", "usb_con_therm_adc", "svooc_mos_btb_therm",
				"sub_batt_con_therm_adc";
};

&qupv3_se15_i2c {
	status = "okay";
	qcom,clk-freq-out = <400000>;

	oplus_sc8547d:oplus,sc8547d@6a {
		status = "okay";
		compatible = "oplus,sc8547d";
		reg = <0x6A>;
		oplus,use_vooc_phy;
		oplus,use_ufcs_phy;
		oplus,vac_support;
		oplus,always_otg_en;

		oplus_spec,irq_gpio = <&tlmm 46 0x00>;

		pinctrl-names = "charging_inter_active", "charging_inter_sleep";
		pinctrl-0 = <&charging_inter_active>;
		pinctrl-1 = <&charging_inter_sleep>;
		oplus_spec,batt_pwd_curr_thd1 = <3000>;
		oplus_spec,batt_pwd_vol_thd1 = <4600>;

		oplus,ic_type = <OPLUS_CHG_IC_VPHY>;
		oplus,ic_index = <0>;
		oplus,vooc-version = <VOOC_VERSION_5_0>;

		oplus_sc8547_cp: oplus,sc8547_cp {
			oplus,ic_type = <OPLUS_CHG_IC_CP>;
			oplus,ic_index = <0>;
			oplus,ic_func_group = <&sc8547_cp_groups>;
		};
	};
};

&qupv3_se5_i2c {
	status = "okay";
	clock-frequency = <400000>;
	oplus_sc8547_slave: sc8547-charger-slave@6A{
		status = "okay";
		compatible = "oplus,sc8547d";
		reg = <0x6A>;
		ocp_reg = <0xe>;
		ovp_reg = <0x36>;
		oplus,use_slave_cp;

		oplus_spec,irq_gpio = <&tlmm 47 0x00>;

		pinctrl-names = "charging_inter_active", "charging_inter_sleep";
		pinctrl-0 = <&slave_charging_inter_active>;
		pinctrl-1 = <&slave_charging_inter_sleep>;

		oplus_sc8547_slave_cp: oplus,sc8547_slave_cp {
			oplus,ic_type = <OPLUS_CHG_IC_CP>;
			oplus,ic_index = <1>;
		};
	};
};

&tlmm {
	charging_inter_active: charging_inter_active {
		mux {
			pins = "gpio46";
			function = "gpio";
		};
		config {
			pins = "gpio46";
			bias-pull-up; /* NO pull */
			drive-strength = <2>; /* 2 MA */
			input-enable;
		};
	};

	charging_inter_sleep: charging_inter_sleep {
		mux {
			pins = "gpio46";
			function = "gpio";
		};
		config {
			pins = "gpio46";
			bias-pull-up; /* NO pull */
			drive-strength = <2>; /* 2 MA */
			input-enable;
		};
	};
};

&pmiv010x_gpios {
	usbtemp_l_gpio_default: usbtemp_l_gpio_default {
		pins = "gpio6"; //GPIO 6
		function = "normal"; //normal
		bias-high-impedance;
		bias-disable;
	};
	usbtemp_r_gpio_default: usbtemp_r_gpio_default {
		pins = "gpio7"; //GPIO 7
		function = "normal"; //normal
		bias-high-impedance;
		bias-disable;
	};
};

&pmxr2230_gpios {
	subboard_temp_gpio_default: subboard_temp_gpio_default {
		pins = "gpio4"; //GPIO 4
		function = "normal"; //normal
		bias-high-impedance; //DISABLE GPIO4 for ADC
		bias-disable;
	};
	svooc_mos_btb_therm {
		svooc_mos_btb_therm_default: svooc_mos_btb_therm_default {
			pins = "gpio3";
			function = "normal"; //normal
			bias-high-impedance;
			bias-disable;
		};
	};
	batt_con_therm {
		batt_con_therm_default: batt_con_therm_default {
			pins = "gpio7";
			function = "normal"; //normal
			bias-high-impedance;
			bias-disable;
		};
	};
};

&pmk8550_gpios {
	batt_conn_dual_therm {
		batt_conn_dual_therm_default: batt_conn_dual_therm_default {
			pins = "gpio1";
			function = "normal"; //normal
			bias-high-impedance;
			bias-disable;
		};
	};
};

&pmk8550_vadc {
	pinctrl-0 = <&svooc_mos_btb_therm_default>, <&batt_con_therm_default>, <&batt_conn_dual_therm_default>;
	pinctrl-names = "default";

	usb_temp_adc_l {
		reg = <PMIV0104_ADC5_GEN3_AMUX_THM6_GPIO6_100K_PU>;
		label = "usb_temp_adc_l";
		qcom,pre-scaling = <1 1>;
		qcom,ratiometric;
		qcom,hw-settle-time = <200>;
		qcom,scale-fn-type = <OPLUS_ADC_SCALE_HW_CALIB_DEFAULT>;
	};
	usb_temp_adc_r {
		reg = <PMIV0104_ADC5_GEN3_AMUX3_GPIO7_100K_PU>;
		label = "usb_temp_adc_r";
		qcom,pre-scaling = <1 1>;
		qcom,ratiometric;
		qcom,hw-settle-time = <200>;
		qcom,scale-fn-type = <OPLUS_ADC_SCALE_HW_CALIB_DEFAULT>;
	};

	subboard_temp_adc {
		reg = <PM8550_ADC5_GEN3_AMUX2_GPIO4_100K_PU>;
		label = "subboard_temp_adc";
		qcom,pre-scaling = <1 1>;
		qcom,ratiometric;
		qcom,hw-settle-time = <200>;
		qcom,adc-tm-type = <2>;
	};
	batt_con_therm_adc {
		reg = <PM8550_ADC5_GEN3_AMUX3_GPIO7_100K_PU>;
		label = "batt_con_therm_adc";
		qcom,ratiometric;
		qcom,hw-settle-time = <200>;
		qcom,pre-scaling = <1 1>;
	};
	sub_batt_con_therm_adc {
		reg = <PMK8550_ADC5_GEN3_AMUX_THM2_GPIO1_100K_PU>;
		label = "sub_batt_con_therm_adc";
		qcom,ratiometric;
		qcom,hw-settle-time = <200>;
		qcom,pre-scaling = <1 1>;
	};
	usb_con_therm_adc {
		reg = <PMIV0104_ADC5_GEN3_AMUX_THM4_USB_THERM_100K_PU>;
		label = "usb_con_therm_adc";
		qcom,ratiometric;
		qcom,hw-settle-time = <200>;
		qcom,pre-scaling = <1 1>;
	};

	svooc_mos_btb_therm {
		reg = <PM8550_ADC5_GEN3_AMUX1_GPIO3_100K_PU>;
		label = "svooc_mos_btb_therm";
		qcom,ratiometric;
		qcom,hw-settle-time = <200>;
		qcom,pre-scaling = <1 1>;
		qcom,adc-tm-type = <2>;
	};
 	pmiv010x_vbat_sns_qbg {
 		reg = <PMIV0104_ADC5_GEN3_VBAT_SNS_QBG>;
 		label = "pmiv010x_vbat_sns_qbg";
 		qcom,pre-scaling = <1 3>;
 	};
	batt_conn_dual {
		reg = <PMK8550_ADC5_GEN3_AMUX_THM2_GPIO1_100K_PU>;
		label = "batt_conn_dual";
		qcom,ratiometric;
		qcom,hw-settle-time = <200>;
		qcom,pre-scaling = <1 1>;
		qcom,adc-tm-type = <2>;
	};
};
&spmi_bus {
	qcom,pmr735b@5 {
		status = "disabled";
	};
};
&thermal_zones {
	svooc_mos_btb_usr {
		polling-delay-passive = <0>;
		polling-delay = <0>;
		thermal-governor = "user_space";
		thermal-sensors = <&pmk8550_vadc PM8550_ADC5_GEN3_AMUX1_GPIO3_100K_PU>;
		wake-capable-sensor;
		trips {
			active-config0 {
				temperature = <125000>;
				hysteresis = <1000>;
				type = "passive";
			};
		};
	};
	batt_conn_dual {
		polling-delay-passive = <0>;
		polling-delay = <0>;
		thermal-governor = "user_space";
		thermal-sensors = <&pmk8550_vadc PMK8550_ADC5_GEN3_AMUX_THM2_GPIO1_100K_PU>;
		wake-capable-sensor;
		trips {
			active-config0 {
				temperature = <125000>;
				hysteresis = <1000>;
				type = "passive";
			};
		};
	};
	subboard_temp {
		polling-delay-passive = <0>;
		polling-delay = <0>;
		thermal-governor = "user_space";
		thermal-sensors = <&pmk8550_vadc PM8550_ADC5_GEN3_AMUX2_GPIO4_100K_PU>;
		wake-capable-sensor;
		trips {
			active-config0 {
				temperature = <125000>;
				hysteresis = <1000>;
				type = "passive";
			};
		};
	};
};

&pm8550ve_f_gpios {
	dischg_enable: dischg_enable {
		pins = "gpio7";
		function = "normal";
		bias-disable;
		output-high;
	};
	dischg_disable: dischg_disable {
		pins = "gpio7";
		function = "normal";
		bias-disable;
		output-low;
	};
};

&qupv3_se8_i2c_pins {
	qupv3_se8_i2c_sda_active_oplus: qupv3_se8_i2c_sda_active_oplus {
		mux {
			pins = "gpio0";
			function = "qup2_se0_l0";
		};
		config {
			pins = "gpio0";
			drive-strength = <2>;
			bias-disable;
		};
	};
	qupv3_se8_i2c_scl_active_oplus: qupv3_se8_i2c_scl_active_oplus {
		mux {
			pins = "gpio1";
			function = "qup2_se0_l1";
		};
		config {
			pins = "gpio1";
			drive-strength = <2>;
			bias-disable;
		};
	};
	qupv3_se8_i2c_pulldown_oplus: qupv3_se8_i2c_pulldown_oplus {
		mux {
			pins = "gpio0", "gpio1";
			function = "gpio";
		};
		config {
			pins = "gpio0", "gpio1";
			drive-strength = <2>;
			bias-pull-down;
			output-low;
		};
	};
	qupv3_se8_i2c_pullup_oplus: qupv3_se8_i2c_pullup_oplus {
		mux {
			pins = "gpio0", "gpio1";
			function = "gpio";
		};
		config {
			pins = "gpio0", "gpio1";
			drive-strength = <2>;
			bias-pull-up;
			input-enable;
		};
	};
};

&qupv3_se8_i2c {
	status = "ok";
	qcom,clk-freq-out = <100000>;
	pinctrl-names = "default", "sleep", "pulldown", "pullup";
	pinctrl-0 = <&qupv3_se8_i2c_sda_active_oplus>, <&qupv3_se8_i2c_scl_active_oplus>;
	pinctrl-1 = <&qupv3_se8_i2c_sleep>;
	pinctrl-2 = <&qupv3_se8_i2c_pulldown_oplus>;
	pinctrl-3 = <&qupv3_se8_i2c_pullup_oplus>;
	oplus_ext_gauge: bq27541-battery@55 {
		status = "okay";
		compatible = "oplus,bq27541-battery";
		reg = <0x55>;
		qcom,modify-soc-calibration;
		oplus,batt_num = <1>;
		oplus,support_extern_cmd;
		oplus,calib_info_save_support;
		oplus,batt_nfg8011b;
		oplus,ic_type = <OPLUS_CHG_IC_GAUGE>;
		oplus,ic_index = <1>;
	};
};
